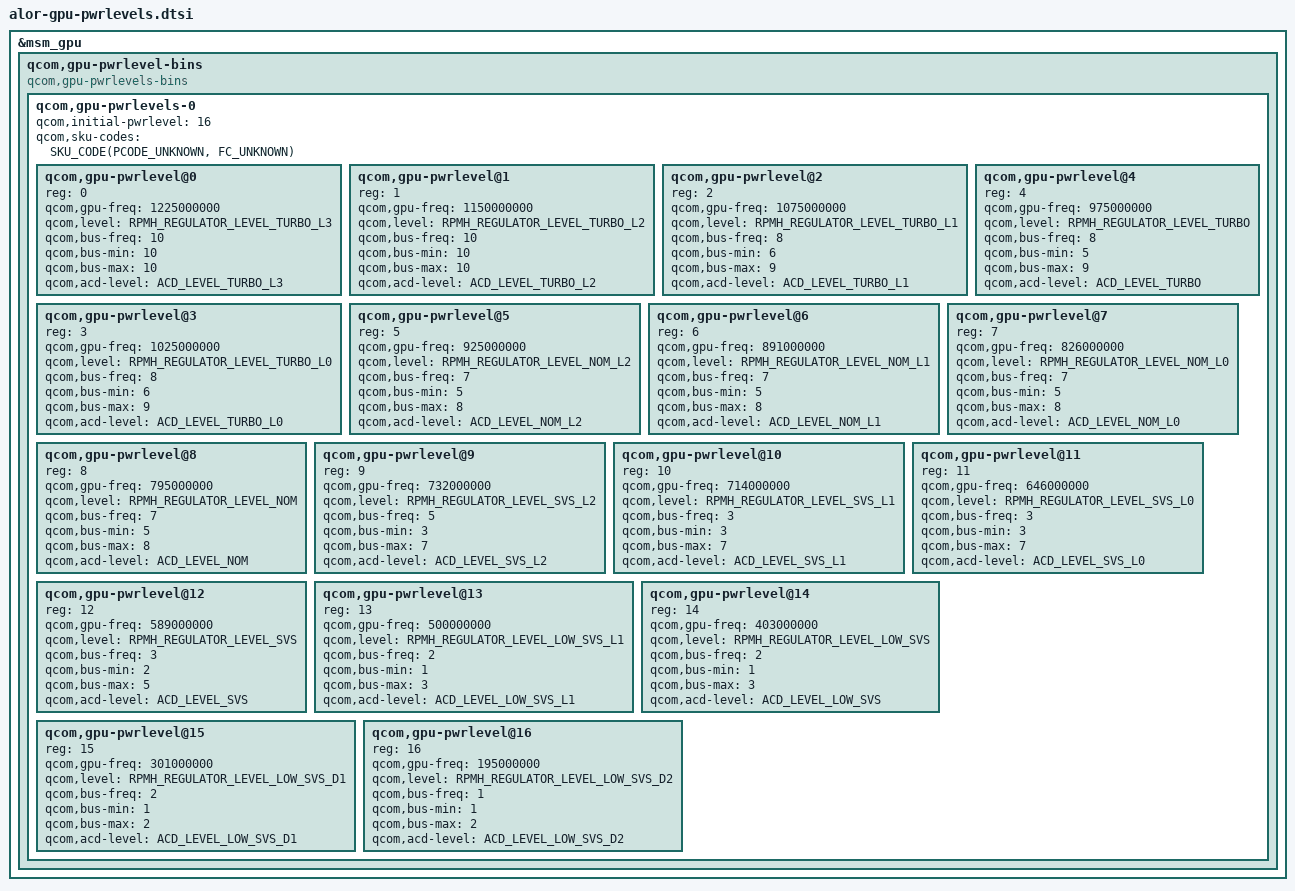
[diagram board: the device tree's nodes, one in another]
// SPDX-License-Identifier: BSD-3-Clause
/*
 * Copyright (c) Qualcomm Technologies, Inc. and/or its subsidiaries.
 */

#define ACD_LEVEL_TURBO_L3       0x88295FFD
#define ACD_LEVEL_TURBO_L2       0xA8295FFD
#define ACD_LEVEL_TURBO_L1       0x882A5FFD
#define ACD_LEVEL_TURBO_L0       0xA82A5FFD
#define ACD_LEVEL_TURBO          0x882B5FFD
#define ACD_LEVEL_NOM_L2         0xA82B5FFD
#define ACD_LEVEL_NOM_L1         0xA82B5FFD
#define ACD_LEVEL_NOM_L0         0x882C5FFD
#define ACD_LEVEL_NOM            0x882D5FFD
#define ACD_LEVEL_SVS_L2         0x882E5FFD
#define ACD_LEVEL_SVS_L1         0x882F5FFD
#define ACD_LEVEL_SVS_L0         0x882F5FFD
#define ACD_LEVEL_SVS            0xC02B5FFD
#define ACD_LEVEL_LOW_SVS_L1     0xC8295FFD
#define ACD_LEVEL_LOW_SVS        0xC8295FFD
#define ACD_LEVEL_LOW_SVS_D1     0xC82F5FFD
#define ACD_LEVEL_LOW_SVS_D2     0xC82F5FFD

&msm_gpu {
	/* Power levels */
	qcom,gpu-pwrlevel-bins {
		#address-cells = <1>;
		#size-cells = <0>;

		compatible = "qcom,gpu-pwrlevels-bins";

		/* Keep the pwrlevel bins sorted on the highest qcom,gpu-freq */
		qcom,gpu-pwrlevels-0 {
			#address-cells = <1>;
			#size-cells = <0>;

			qcom,initial-pwrlevel = <16>;
			qcom,sku-codes = <SKU_CODE(PCODE_UNKNOWN, FC_UNKNOWN)>;

			/* TURBO_L3 */
			qcom,gpu-pwrlevel@0 {
				reg = <0>;
				qcom,gpu-freq = <1225000000>;
				qcom,level = <RPMH_REGULATOR_LEVEL_TURBO_L3>;

				qcom,bus-freq = <10>;
				qcom,bus-min = <10>;
				qcom,bus-max = <10>;

				qcom,acd-level = <ACD_LEVEL_TURBO_L3>;
			};

			/* TURBO_L2 */
			qcom,gpu-pwrlevel@1 {
				reg = <1>;
				qcom,gpu-freq = <1150000000>;
				qcom,level = <RPMH_REGULATOR_LEVEL_TURBO_L2>;

				qcom,bus-freq = <10>;
				qcom,bus-min = <10>;
				qcom,bus-max = <10>;

				qcom,acd-level = <ACD_LEVEL_TURBO_L2>;
			};

			/* TURBO_L1 */
			qcom,gpu-pwrlevel@2 {
				reg = <2>;
				qcom,gpu-freq = <1075000000>;
				qcom,level = <RPMH_REGULATOR_LEVEL_TURBO_L1>;

				qcom,bus-freq = <8>;
				qcom,bus-min = <6>;
				qcom,bus-max = <9>;

				qcom,acd-level = <ACD_LEVEL_TURBO_L1>;
			};

			/* TURBO_L0 */
			qcom,gpu-pwrlevel@3 {
				reg = <3>;
				qcom,gpu-freq = <1025000000>;
				qcom,level = <RPMH_REGULATOR_LEVEL_TURBO_L0>;

				qcom,bus-freq = <8>;
				qcom,bus-min = <6>;
				qcom,bus-max = <9>;

				qcom,acd-level = <ACD_LEVEL_TURBO_L0>;
			};

			/* TURBO */
			qcom,gpu-pwrlevel@4 {
				reg = <4>;
				qcom,gpu-freq = <975000000>;
				qcom,level = <RPMH_REGULATOR_LEVEL_TURBO>;

				qcom,bus-freq = <8>;
				qcom,bus-min = <5>;
				qcom,bus-max = <9>;

				qcom,acd-level = <ACD_LEVEL_TURBO>;
			};

			/* NOM_L2 */
			qcom,gpu-pwrlevel@5 {
				reg = <5>;
				qcom,gpu-freq = <925000000>;
				qcom,level = <RPMH_REGULATOR_LEVEL_NOM_L2>;

				qcom,bus-freq = <7>;
				qcom,bus-min = <5>;
				qcom,bus-max = <8>;

				qcom,acd-level = <ACD_LEVEL_NOM_L2>;
			};

			/* NOM_L1 */
			qcom,gpu-pwrlevel@6 {
				reg = <6>;
				qcom,gpu-freq = <891000000>;
				qcom,level = <RPMH_REGULATOR_LEVEL_NOM_L1>;

				qcom,bus-freq = <7>;
				qcom,bus-min = <5>;
				qcom,bus-max = <8>;

				qcom,acd-level = <ACD_LEVEL_NOM_L1>;
			};

			/* NOM_L0 */
			qcom,gpu-pwrlevel@7 {
				reg = <7>;
				qcom,gpu-freq = <826000000>;
				qcom,level = <RPMH_REGULATOR_LEVEL_NOM_L0>;

				qcom,bus-freq = <7>;
				qcom,bus-min = <5>;
				qcom,bus-max = <8>;

				qcom,acd-level = <ACD_LEVEL_NOM_L0>;
			};

			/* NOM */
			qcom,gpu-pwrlevel@8 {
				reg = <8>;
				qcom,gpu-freq = <795000000>;
				qcom,level = <RPMH_REGULATOR_LEVEL_NOM>;

				qcom,bus-freq = <7>;
				qcom,bus-min = <5>;
				qcom,bus-max = <8>;

				qcom,acd-level = <ACD_LEVEL_NOM>;
			};

			/* SVS_L2 */
			qcom,gpu-pwrlevel@9 {
				reg = <9>;
				qcom,gpu-freq = <732000000>;
				qcom,level = <RPMH_REGULATOR_LEVEL_SVS_L2>;

				qcom,bus-freq = <5>;
				qcom,bus-min = <3>;
				qcom,bus-max = <7>;

				qcom,acd-level = <ACD_LEVEL_SVS_L2>;
			};

			/* SVS_L1 */
			qcom,gpu-pwrlevel@10 {
				reg = <10>;
				qcom,gpu-freq = <714000000>;
				qcom,level = <RPMH_REGULATOR_LEVEL_SVS_L1>;

				qcom,bus-freq = <3>;
				qcom,bus-min = <3>;
				qcom,bus-max = <7>;

				qcom,acd-level = <ACD_LEVEL_SVS_L1>;
			};

			/* SVS_L0 */
			qcom,gpu-pwrlevel@11 {
				reg = <11>;
				qcom,gpu-freq = <646000000>;
				qcom,level = <RPMH_REGULATOR_LEVEL_SVS_L0>;

				qcom,bus-freq = <3>;
				qcom,bus-min = <3>;
				qcom,bus-max = <7>;

				qcom,acd-level = <ACD_LEVEL_SVS_L0>;
			};

			/* SVS */
			qcom,gpu-pwrlevel@12 {
				reg = <12>;
				qcom,gpu-freq = <589000000>;
				qcom,level = <RPMH_REGULATOR_LEVEL_SVS>;

				qcom,bus-freq = <3>;
				qcom,bus-min = <2>;
				qcom,bus-max = <5>;

				qcom,acd-level = <ACD_LEVEL_SVS>;
			};

			/* LOW_SVS_L1 */
			qcom,gpu-pwrlevel@13 {
				reg = <13>;
				qcom,gpu-freq = <500000000>;
				qcom,level = <RPMH_REGULATOR_LEVEL_LOW_SVS_L1>;

				qcom,bus-freq = <2>;
				qcom,bus-min = <1>;
				qcom,bus-max = <3>;

				qcom,acd-level = <ACD_LEVEL_LOW_SVS_L1>;

			};

			/* Low_SVS */
			qcom,gpu-pwrlevel@14 {
				reg = <14>;
				qcom,gpu-freq = <403000000>;
				qcom,level = <RPMH_REGULATOR_LEVEL_LOW_SVS>;

				qcom,bus-freq = <2>;
				qcom,bus-min = <1>;
				qcom,bus-max = <3>;

				qcom,acd-level = <ACD_LEVEL_LOW_SVS>;
			};

			/* Low_SVS_D1 */
			qcom,gpu-pwrlevel@15 {
				reg = <15>;
				qcom,gpu-freq = <301000000>;
				qcom,level = <RPMH_REGULATOR_LEVEL_LOW_SVS_D1>;

				qcom,bus-freq = <2>;
				qcom,bus-min = <1>;
				qcom,bus-max = <2>;

				qcom,acd-level = <ACD_LEVEL_LOW_SVS_D1>;
			};

			/* Low_SVS_D2 */
			qcom,gpu-pwrlevel@16 {
				reg = <16>;
				qcom,gpu-freq = <195000000>;
				qcom,level = <RPMH_REGULATOR_LEVEL_LOW_SVS_D2>;

				qcom,bus-freq = <1>;
				qcom,bus-min = <1>;
				qcom,bus-max = <2>;

				qcom,acd-level = <ACD_LEVEL_LOW_SVS_D2>;
			};
		};
	};
};
